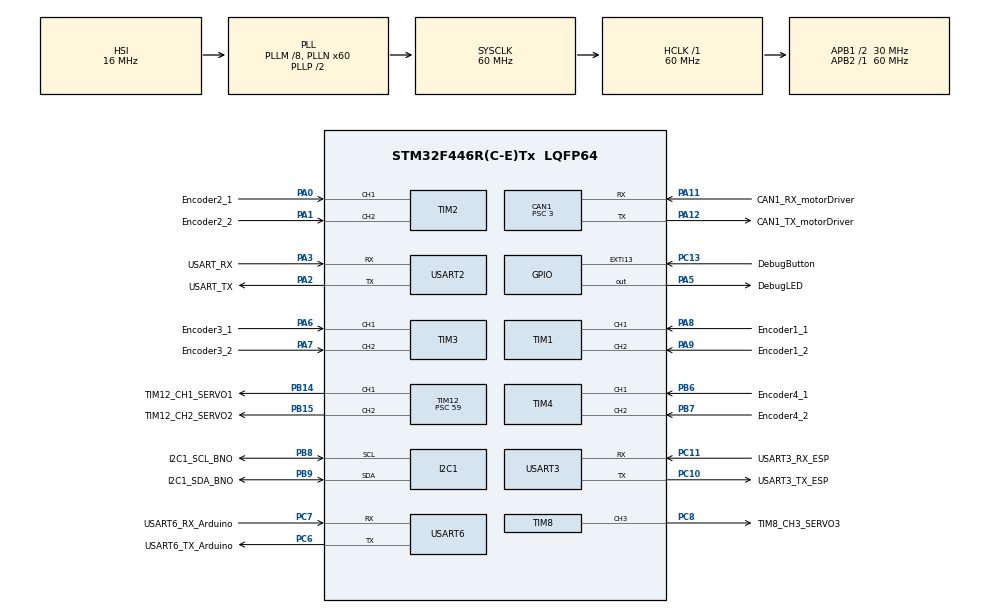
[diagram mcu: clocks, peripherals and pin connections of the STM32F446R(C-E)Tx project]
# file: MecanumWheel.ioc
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CAN1.BS1=CAN_BS1_7TQ
CAN1.BS2=CAN_BS2_2TQ
CAN1.CalculateBaudRate=1000000
CAN1.CalculateTimeBit=1000
CAN1.CalculateTimeQuantum=100.0
CAN1.Prescaler=3
I2C1.I2C_Mode=I2C_Fast
Mcu.Family=STM32F4
Mcu.Name=STM32F446R(C-E)Tx
Mcu.Package=LQFP64
NVIC.CAN1_RX0_IRQn=true\:0\:0\:false\:false\:true\:true\:true\:true
NVIC.PriorityGroup=NVIC_PRIORITYGROUP_0
NVIC.USART2_IRQn=true\:0\:0\:false\:false\:true\:true\:true\:true
NVIC.USART3_IRQn=true\:0\:0\:false\:false\:true\:true\:true\:true
NVIC.USART6_IRQn=true\:0\:0\:false\:false\:true\:true\:true\:true
PA0-WKUP.GPIO_Label=Encoder2_1
PA0-WKUP.Signal=S_TIM2_CH1_ETR
PA1.GPIO_Label=Encoder2_2
PA1.Signal=S_TIM2_CH2
PA11.GPIO_Label=CAN1_RX_motorDriver
PA11.Mode=CAN_Activate
PA11.Signal=CAN1_RX
PA12.GPIO_Label=CAN1_TX_motorDriver
PA12.Mode=CAN_Activate
PA12.Signal=CAN1_TX
PA13.GPIO_Label=TMS
PA13.Mode=Serial_Wire
PA13.Signal=SYS_JTMS-SWDIO
PA14.GPIO_Label=TCK
PA14.Mode=Serial_Wire
PA14.Signal=SYS_JTCK-SWCLK
PA2.GPIO_Label=USART_TX
PA2.Mode=Asynchronous
PA2.Signal=USART2_TX
PA3.GPIO_Label=USART_RX
PA3.Mode=Asynchronous
PA3.Signal=USART2_RX
PA5.GPIO_Label=DebugLED
PA5.Signal=GPIO_Output
PA6.GPIO_Label=Encoder3_1
PA6.Signal=S_TIM3_CH1
PA7.GPIO_Label=Encoder3_2
PA7.Signal=S_TIM3_CH2
PA8.GPIO_Label=Encoder1_1
PA8.Signal=S_TIM1_CH1
PA9.GPIO_Label=Encoder1_2
PA9.Signal=S_TIM1_CH2
PB14.GPIO_Label=TIM12_CH1_SERVO1
PB14.Signal=S_TIM12_CH1
PB15.GPIO_Label=TIM12_CH2_SERVO2
PB15.Signal=S_TIM12_CH2
PB3.GPIO_Label=SWO
PB3.Signal=SYS_JTDO-SWO
PB6.GPIO_Label=Encoder4_1
PB6.Signal=S_TIM4_CH1
PB7.GPIO_Label=Encoder4_2
PB7.Signal=S_TIM4_CH2
PB8.GPIO_Label=I2C1_SCL_BNO
PB8.Mode=I2C
PB8.Signal=I2C1_SCL
PB9.GPIO_Label=I2C1_SDA_BNO
PB9.Mode=I2C
PB9.Signal=I2C1_SDA
PC10.GPIO_Label=USART3_TX_ESP
PC10.Mode=Asynchronous
PC10.Signal=USART3_TX
PC11.GPIO_Label=USART3_RX_ESP
PC11.Mode=Asynchronous
PC11.Signal=USART3_RX
PC13.GPIO_Label=DebugButton
PC13.GPIO_ModeDefaultEXTI=GPIO_MODE_IT_FALLING
PC13.Signal=GPXTI13
PC14-OSC32_IN.Mode=LSE-External-Oscillator
PC14-OSC32_IN.Signal=RCC_OSC32_IN
PC15-OSC32_OUT.Mode=LSE-External-Oscillator
PC15-OSC32_OUT.Signal=RCC_OSC32_OUT
PC6.GPIO_Label=USART6_TX_Arduino
PC6.Mode=Asynchronous
PC6.Signal=USART6_TX
PC7.GPIO_Label=USART6_RX_Arduino
PC7.Mode=Asynchronous
PC7.Signal=USART6_RX
PC8.GPIO_Label=TIM8_CH3_SERVO3
PC8.Signal=S_TIM8_CH3
PH0-OSC_IN.Mode=HSE-External-Oscillator
PH0-OSC_IN.Signal=RCC_OSC_IN
PH1-OSC_OUT.Mode=HSE-External-Oscillator
PH1-OSC_OUT.Signal=RCC_OSC_OUT
ProjectManager.HeapSize=0x200
ProjectManager.StackSize=0x400
ProjectManager.TargetToolchain=STM32CubeIDE
RCC.48MHZClocksFreq_Value=84000000
RCC.AHBFreq_Value=60000000
RCC.APB1CLKDivider=RCC_HCLK_DIV2
RCC.APB1Freq_Value=30000000
RCC.APB1TimFreq_Value=60000000
RCC.APB2Freq_Value=60000000
RCC.APB2TimFreq_Value=60000000
RCC.CortexFreq_Value=60000000
RCC.FLatency-AdvancedSettings=FLASH_LATENCY_1
RCC.HCLKFreq_Value=60000000
RCC.HSE_VALUE=8000000
RCC.HSI_VALUE=16000000
RCC.PLLM=8
RCC.PLLN=60
RCC.SYSCLKFreq_VALUE=60000000
RCC.SYSCLKSource=RCC_SYSCLKSOURCE_PLLCLK
RCC.USBFreq_Value=60000000
RCC.VCOOutputFreq_Value=120000000
SH.S_TIM12_CH1.0=TIM12_CH1,PWM Generation1 CH1
SH.S_TIM12_CH2.0=TIM12_CH2,PWM Generation2 CH2
SH.S_TIM1_CH1.0=TIM1_CH1,Encoder_Interface
SH.S_TIM1_CH2.0=TIM1_CH2,Encoder_Interface
SH.S_TIM2_CH1_ETR.0=TIM2_CH1,Encoder_Interface
SH.S_TIM2_CH2.0=TIM2_CH2,Encoder_Interface
SH.S_TIM3_CH1.0=TIM3_CH1,Encoder_Interface
SH.S_TIM3_CH2.0=TIM3_CH2,Encoder_Interface
SH.S_TIM4_CH1.0=TIM4_CH1,Encoder_Interface
SH.S_TIM4_CH2.0=TIM4_CH2,Encoder_Interface
SH.S_TIM8_CH3.0=TIM8_CH3,PWM Generation3 CH3
TIM1.EncoderMode=TIM_ENCODERMODE_TI12
TIM12.Channel-PWM\ Generation1\ CH1=TIM_CHANNEL_1
TIM12.Channel-PWM\ Generation2\ CH2=TIM_CHANNEL_2
TIM12.Period=19999
TIM12.Prescaler=59
TIM2.EncoderMode=TIM_ENCODERMODE_TI12
TIM3.EncoderMode=TIM_ENCODERMODE_TI12
TIM4.EncoderMode=TIM_ENCODERMODE_TI12
TIM8.Channel-PWM\ Generation3\ CH3=TIM_CHANNEL_3
TIM8.Period=19999
TIM8.Prescaler=59
USART2.VirtualMode=VM_ASYNC
USART3.VirtualMode=VM_ASYNC
USART6.VirtualMode=VM_ASYNC
board=NUCLEO-F446RE

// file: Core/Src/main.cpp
/* USER CODE BEGIN Header */
/**
  ******************************************************************************
  * @file           : main.c
  * @brief          : Main program body
  ******************************************************************************
  * @attention
  *
  * Copyright (c) 2025 STMicroelectronics.
  * All rights reserved.
  *
  * This software is licensed under terms that can be found in the LICENSE file
  * in the root directory of this software component.
  * If no LICENSE file comes with this software, it is provided AS-IS.
  *
  ******************************************************************************
  */
/* USER CODE END Header */
#include "main.h"
#include "can.h"
#include "i2c.h"
#include "tim.h"
#include "usart.h"
#include "gpio.h"

void SystemClock_Config(void);

int main(void)
{

  /* MCU Configuration--------------------------------------------------------*/

  /* Reset of all peripherals, Initializes the Flash interface and the Systick. */
  HAL_Init();

  /* Configure the system clock */
  SystemClock_Config();

  /* Initialize all configured peripherals */
  MX_GPIO_Init();
  MX_USART2_UART_Init();
  MX_CAN1_Init();
  MX_I2C1_Init();
  MX_USART3_UART_Init();
  MX_TIM1_Init();
  MX_TIM2_Init();
  MX_TIM3_Init();
  MX_TIM4_Init();
  MX_USART6_UART_Init();
  MX_TIM8_Init();
  MX_TIM12_Init();
  /* USER CODE BEGIN 2 */
  user_setup();

  /* USER CODE END 2 */

  /* Infinite loop */
  /* USER CODE BEGIN WHILE */
  while (1)
  {
    user_loop();
    /* USER CODE END WHILE */

  }
}

void SystemClock_Config(void)
{
  RCC_OscInitTypeDef RCC_OscInitStruct = {0};
  RCC_ClkInitTypeDef RCC_ClkInitStruct = {0};

  /** Configure the main internal regulator output voltage
  */
  __HAL_RCC_PWR_CLK_ENABLE();
  __HAL_PWR_VOLTAGESCALING_CONFIG(PWR_REGULATOR_VOLTAGE_SCALE3);

  /** Initializes the RCC Oscillators according to the specified parameters
  * in the RCC_OscInitTypeDef structure.
  */
  RCC_OscInitStruct.OscillatorType = RCC_OSCILLATORTYPE_HSI;
  RCC_OscInitStruct.HSIState = RCC_HSI_ON;
  RCC_OscInitStruct.HSICalibrationValue = RCC_HSICALIBRATION_DEFAULT;
  RCC_OscInitStruct.PLL.PLLState = RCC_PLL_ON;
  RCC_OscInitStruct.PLL.PLLSource = RCC_PLLSOURCE_HSI;
  RCC_OscInitStruct.PLL.PLLM = 8;
  RCC_OscInitStruct.PLL.PLLN = 60;
  RCC_OscInitStruct.PLL.PLLP = RCC_PLLP_DIV2;
  RCC_OscInitStruct.PLL.PLLQ = 2;
  RCC_OscInitStruct.PLL.PLLR = 2;
  if (HAL_RCC_OscConfig(&RCC_OscInitStruct) != HAL_OK)
  {
    Error_Handler();
  }

  /** Initializes the CPU, AHB and APB buses clocks
  */
  RCC_ClkInitStruct.ClockType = RCC_CLOCKTYPE_HCLK|RCC_CLOCKTYPE_SYSCLK
                              |RCC_CLOCKTYPE_PCLK1|RCC_CLOCKTYPE_PCLK2;
  RCC_ClkInitStruct.SYSCLKSource = RCC_SYSCLKSOURCE_PLLCLK;
  RCC_ClkInitStruct.AHBCLKDivider = RCC_SYSCLK_DIV1;
  RCC_ClkInitStruct.APB1CLKDivider = RCC_HCLK_DIV2;
  RCC_ClkInitStruct.APB2CLKDivider = RCC_HCLK_DIV1;

  if (HAL_RCC_ClockConfig(&RCC_ClkInitStruct, FLASH_LATENCY_1) != HAL_OK)
  {
    Error_Handler();
  }
}

void Error_Handler(void)
{
  __disable_irq();
  while (1)
  {
  }
}
